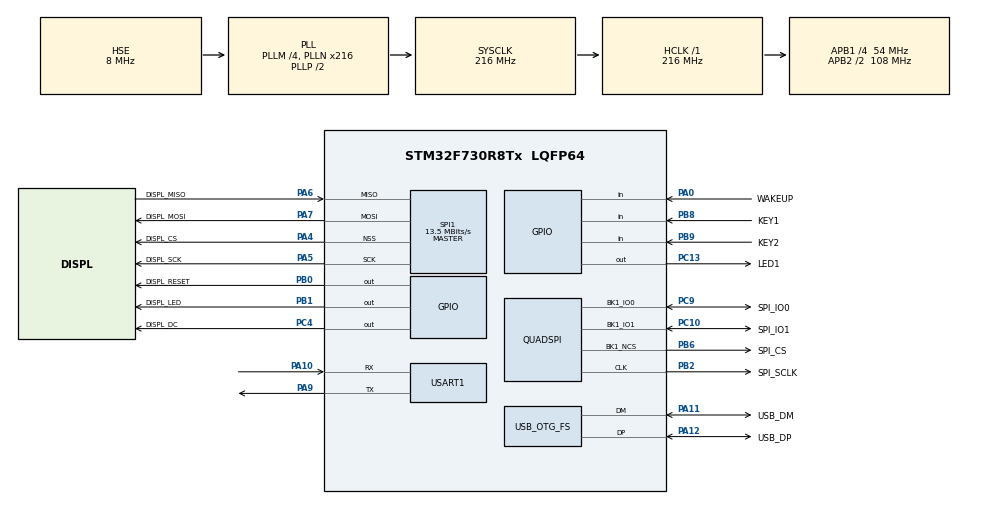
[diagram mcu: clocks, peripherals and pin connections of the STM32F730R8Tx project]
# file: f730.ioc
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CORTEX_M7.ART_ACCLERATOR_ENABLE=1
CORTEX_M7.AccessPermission-Cortex_Memory_Protection_Unit_Region0_Settings=MPU_REGION_FULL_ACCESS
CORTEX_M7.BaseAddress-Cortex_Memory_Protection_Unit_Region0_Settings=0x90000000
CORTEX_M7.CPU_DCache=Disabled
CORTEX_M7.CPU_ICache=Enabled
CORTEX_M7.DisableExec-Cortex_Memory_Protection_Unit_Region0_Settings=MPU_INSTRUCTION_ACCESS_ENABLE
CORTEX_M7.Enable-Cortex_Memory_Protection_Unit_Region0_Settings=MPU_REGION_ENABLE
CORTEX_M7.FlashInterface=TCM_Enabled
CORTEX_M7.IsCacheable-Cortex_Memory_Protection_Unit_Region0_Settings=MPU_ACCESS_CACHEABLE
CORTEX_M7.IsShareable-Cortex_Memory_Protection_Unit_Region0_Settings=MPU_ACCESS_NOT_SHAREABLE
CORTEX_M7.MPU_Control=MPU_PRIVILEGED_DEFAULT
CORTEX_M7.PREFETCH_ENABLE=1
CORTEX_M7.Size-Cortex_Memory_Protection_Unit_Region0_Settings=MPU_REGION_SIZE_4MB
FATFS._FS_EXFAT=1
FATFS._USE_LFN=2
FREERTOS.Tasks01=LogicTask,24,4028,BusinessLogicTask,Default,NULL,Dynamic,NULL,NULL
FREERTOS.configTOTAL_HEAP_SIZE=150360
Mcu.Family=STM32F7
Mcu.Name=STM32F730R8Tx
Mcu.Package=LQFP64
NVIC.OTG_FS_IRQn=true\:5\:0\:true\:false\:true\:false\:false\:true
NVIC.PriorityGroup=NVIC_PRIORITYGROUP_4
NVIC.USART1_IRQn=true\:5\:0\:true\:false\:true\:false\:true\:true
PA0-WKUP.GPIO_Label=WAKEUP
PA0-WKUP.Signal=GPIO_Input
PA10.Mode=Asynchronous
PA10.Signal=USART1_RX
PA11.GPIO_Label=USB_DM
PA11.Mode=Host_Only
PA11.Signal=USB_OTG_FS_DM
PA12.GPIO_Label=USB_DP
PA12.Mode=Host_Only
PA12.Signal=USB_OTG_FS_DP
PA13.GPIO_Label=SWDIO
PA13.Mode=Serial_Wire
PA13.Signal=SYS_JTMS-SWDIO
PA14.GPIO_Label=SWCLK
PA14.Mode=Serial_Wire
PA14.Signal=SYS_JTCK-SWCLK
PA4.GPIO_Label=DISPL_CS
PA4.Mode=NSS_Signal_Hard_Output
PA4.Signal=SPI1_NSS
PA5.GPIO_Label=DISPL_SCK
PA5.Mode=Full_Duplex_Master
PA5.Signal=SPI1_SCK
PA6.GPIO_Label=DISPL_MISO
PA6.Mode=Full_Duplex_Master
PA6.Signal=SPI1_MISO
PA7.GPIO_Label=DISPL_MOSI
PA7.Mode=Full_Duplex_Master
PA7.Signal=SPI1_MOSI
PA9.Mode=Asynchronous
PA9.Signal=USART1_TX
PB0.GPIO_Label=DISPL_RESET
PB0.Signal=GPIO_Output
PB1.GPIO_Label=DISPL_LED
PB1.Signal=GPIO_Output
PB2.GPIO_Label=SPI_SCLK
PB2.Mode=Single Bank 1 2IOs
PB2.Signal=QUADSPI_CLK
PB6.GPIO_Label=SPI_CS
PB6.Mode=Single Bank 1 2IOs
PB6.Signal=QUADSPI_BK1_NCS
PB8.GPIO_Label=KEY1
PB8.Signal=GPIO_Input
PB9.GPIO_Label=KEY2
PB9.Signal=GPIO_Input
PC10.GPIO_Label=SPI_IO1
PC10.Mode=Single Bank 1 2IOs
PC10.Signal=QUADSPI_BK1_IO1
PC13.GPIO_Label=LED1
PC13.Signal=GPIO_Output
PC14-OSC32_IN.Mode=LSE-External-Oscillator
PC14-OSC32_IN.Signal=RCC_OSC32_IN
PC15-OSC32_OUT.Mode=LSE-External-Oscillator
PC15-OSC32_OUT.Signal=RCC_OSC32_OUT
PC4.GPIO_Label=DISPL_DC
PC4.Signal=GPIO_Output
PC9.GPIO_Label=SPI_IO0
PC9.Mode=Single Bank 1 2IOs
PC9.Signal=QUADSPI_BK1_IO0
PH0-OSC_IN.Mode=HSE-External-Oscillator
PH0-OSC_IN.Signal=RCC_OSC_IN
PH1-OSC_OUT.Mode=HSE-External-Oscillator
PH1-OSC_OUT.Signal=RCC_OSC_OUT
ProjectManager.HeapSize=0x8200
ProjectManager.StackSize=0x200
ProjectManager.TargetToolchain=STM32CubeIDE
QUADSPI.ChipSelectHighTime=QSPI_CS_HIGH_TIME_1_CYCLE
QUADSPI.ClockPrescaler=10
QUADSPI.FifoThreshold=4
QUADSPI.FlashSize=21
QUADSPI.SampleShifting=QSPI_SAMPLE_SHIFTING_NONE
RCC.AHBFreq_Value=216000000
RCC.APB1CLKDivider=RCC_HCLK_DIV4
RCC.APB1Freq_Value=54000000
RCC.APB1TimFreq_Value=108000000
RCC.APB2CLKDivider=RCC_HCLK_DIV2
RCC.APB2Freq_Value=108000000
RCC.APB2TimFreq_Value=216000000
RCC.CortexFreq_Value=216000000
RCC.EnbaleCSS=true
RCC.HCLKFreq_Value=216000000
RCC.HSE_VALUE=8000000
RCC.HSI_VALUE=16000000
RCC.PLLM=4
RCC.PLLN=216
RCC.PLLQ=9
RCC.SYSCLKFreq_VALUE=216000000
RCC.SYSCLKSource=RCC_SYSCLKSOURCE_PLLCLK
RCC.USBFreq_Value=48000000
RCC.VCOOutputFreq_Value=432000000
SPI1.BaudRatePrescaler=SPI_BAUDRATEPRESCALER_8
SPI1.CalculateBaudRate=13.5 MBits/s
SPI1.DataSize=SPI_DATASIZE_8BIT
SPI1.Direction=SPI_DIRECTION_2LINES
SPI1.Mode=SPI_MODE_MASTER
SPI1.VirtualNSS=VM_NSSHARD
SPI1.VirtualType=VM_MASTER
USART1.VirtualMode-Asynchronous=VM_ASYNC
USB_HOST.USBH_HandleTypeDef-MSC_FS=hUsbHostFS
USB_HOST.USBH_USE_OS-MSC_FS=0
USB_HOST.VirtualModeFS=Msc
USB_OTG_FS.VirtualMode=Host_Only
USB_OTG_FS.phy_itface=HCD_PHY_EMBEDDED
VP_FATFS_VS_USB.Mode=USB
VP_FREERTOS_VS_CMSIS_V2.Mode=CMSIS_V2
VP_USB_HOST_VS_USB_HOST_MSC_FS.Mode=MSC_FS
board=custom

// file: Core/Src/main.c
/* USER CODE BEGIN Header */
/**
  ******************************************************************************
  * @file           : main.c
  * @brief          : Main program body
  ******************************************************************************
  * @attention
  *
  * <h2><center>&copy; Copyright (c) 2020 STMicroelectronics.
  * All rights reserved.</center></h2>
  *
  * This software component is licensed by ST under Ultimate Liberty license
  * SLA0044, the "License"; You may not use this file except in compliance with
  * the License. You may obtain a copy of the License at:
  *                             www.st.com/SLA0044
  *
  ******************************************************************************
  */
/* USER CODE END Header */
#include "main.h"
#include "cmsis_os.h"
#include "fatfs.h"
#include "usb_host.h"

/* USER CODE BEGIN Includes */
#include "dqspi.h"
#include "app_config.h"

/* USER CODE END Includes */

QSPI_HandleTypeDef hqspi;

SPI_HandleTypeDef hspi1;

UART_HandleTypeDef huart1;

/* Definitions for LogicTask */
osThreadId_t LogicTaskHandle;
const osThreadAttr_t LogicTask_attributes = {
  .name = "LogicTask",
  .priority = (osPriority_t) osPriorityNormal,
  .stack_size = 4028 * 4
};

void SystemClock_Config(void);
static void MPU_Config(void);
static void MX_GPIO_Init(void);
static void MX_QUADSPI_Init(void);
static void MX_USART1_UART_Init(void);
static void MX_SPI1_Init(void);
void BusinessLogicTask(void *argument);

int main(void)
{

  /* MPU Configuration--------------------------------------------------------*/
  MPU_Config();

  /* Enable I-Cache---------------------------------------------------------*/
  SCB_EnableICache();

  /* MCU Configuration--------------------------------------------------------*/

  /* Reset of all peripherals, Initializes the Flash interface and the Systick. */
  HAL_Init();

  /* Configure the system clock */
  SystemClock_Config();

  /* Initialize all configured peripherals */
  MX_GPIO_Init();
  MX_QUADSPI_Init();
  MX_USART1_UART_Init();
  MX_FATFS_Init();
  MX_SPI1_Init();
  /* USER CODE BEGIN 2 */
  DQSpiMemoryMapped();

  /* USER CODE END 2 */

  /* Init scheduler */
  osKernelInitialize();

  /* Create the thread(s) */
  /* creation of LogicTask */
  LogicTaskHandle = osThreadNew(BusinessLogicTask, NULL, &LogicTask_attributes);

  /* Start scheduler */
  osKernelStart();

  /* We should never get here as control is now taken by the scheduler */
  /* Infinite loop */
  while (1)
  {

  }
}

void SystemClock_Config(void)
{
  RCC_OscInitTypeDef RCC_OscInitStruct = {0};
  RCC_ClkInitTypeDef RCC_ClkInitStruct = {0};
  RCC_PeriphCLKInitTypeDef PeriphClkInitStruct = {0};

  /** Configure LSE Drive Capability
  */
  HAL_PWR_EnableBkUpAccess();
  /** Configure the main internal regulator output voltage
  */
  __HAL_RCC_PWR_CLK_ENABLE();
  __HAL_PWR_VOLTAGESCALING_CONFIG(PWR_REGULATOR_VOLTAGE_SCALE1);
  /** Initializes the RCC Oscillators according to the specified parameters
  * in the RCC_OscInitTypeDef structure.
  */
  RCC_OscInitStruct.OscillatorType = RCC_OSCILLATORTYPE_HSE;
  RCC_OscInitStruct.HSEState = RCC_HSE_ON;
  RCC_OscInitStruct.PLL.PLLState = RCC_PLL_ON;
  RCC_OscInitStruct.PLL.PLLSource = RCC_PLLSOURCE_HSE;
  RCC_OscInitStruct.PLL.PLLM = 4;
  RCC_OscInitStruct.PLL.PLLN = 216;
  RCC_OscInitStruct.PLL.PLLP = RCC_PLLP_DIV2;
  RCC_OscInitStruct.PLL.PLLQ = 9;
  if (HAL_RCC_OscConfig(&RCC_OscInitStruct) != HAL_OK)
  {
    Error_Handler();
  }
  /** Activate the Over-Drive mode
  */
  if (HAL_PWREx_EnableOverDrive() != HAL_OK)
  {
    Error_Handler();
  }
  /** Initializes the CPU, AHB and APB buses clocks
  */
  RCC_ClkInitStruct.ClockType = RCC_CLOCKTYPE_HCLK|RCC_CLOCKTYPE_SYSCLK
                              |RCC_CLOCKTYPE_PCLK1|RCC_CLOCKTYPE_PCLK2;
  RCC_ClkInitStruct.SYSCLKSource = RCC_SYSCLKSOURCE_PLLCLK;
  RCC_ClkInitStruct.AHBCLKDivider = RCC_SYSCLK_DIV1;
  RCC_ClkInitStruct.APB1CLKDivider = RCC_HCLK_DIV4;
  RCC_ClkInitStruct.APB2CLKDivider = RCC_HCLK_DIV2;

  if (HAL_RCC_ClockConfig(&RCC_ClkInitStruct, FLASH_LATENCY_7) != HAL_OK)
  {
    Error_Handler();
  }
  PeriphClkInitStruct.PeriphClockSelection = RCC_PERIPHCLK_USART1|RCC_PERIPHCLK_CLK48;
  PeriphClkInitStruct.Usart1ClockSelection = RCC_USART1CLKSOURCE_PCLK2;
  PeriphClkInitStruct.Clk48ClockSelection = RCC_CLK48SOURCE_PLL;
  if (HAL_RCCEx_PeriphCLKConfig(&PeriphClkInitStruct) != HAL_OK)
  {
    Error_Handler();
  }
  /** Enables the Clock Security System
  */
  HAL_RCC_EnableCSS();
}

static void MX_QUADSPI_Init(void)
{

  /* QUADSPI parameter configuration*/
  hqspi.Instance = QUADSPI;
  hqspi.Init.ClockPrescaler = 10;
  hqspi.Init.FifoThreshold = 4;
  hqspi.Init.SampleShifting = QSPI_SAMPLE_SHIFTING_NONE;
  hqspi.Init.FlashSize = 21;
  hqspi.Init.ChipSelectHighTime = QSPI_CS_HIGH_TIME_1_CYCLE;
  hqspi.Init.ClockMode = QSPI_CLOCK_MODE_0;
  hqspi.Init.FlashID = QSPI_FLASH_ID_1;
  hqspi.Init.DualFlash = QSPI_DUALFLASH_DISABLE;
  if (HAL_QSPI_Init(&hqspi) != HAL_OK)
  {
    Error_Handler();
  }

}

static void MX_SPI1_Init(void)
{

  /* SPI1 parameter configuration*/
  hspi1.Instance = SPI1;
  hspi1.Init.Mode = SPI_MODE_MASTER;
  hspi1.Init.Direction = SPI_DIRECTION_2LINES;
  hspi1.Init.DataSize = SPI_DATASIZE_8BIT;
  hspi1.Init.CLKPolarity = SPI_POLARITY_LOW;
  hspi1.Init.CLKPhase = SPI_PHASE_1EDGE;
  hspi1.Init.NSS = SPI_NSS_HARD_OUTPUT;
  hspi1.Init.BaudRatePrescaler = SPI_BAUDRATEPRESCALER_8;
  hspi1.Init.FirstBit = SPI_FIRSTBIT_MSB;
  hspi1.Init.TIMode = SPI_TIMODE_DISABLE;
  hspi1.Init.CRCCalculation = SPI_CRCCALCULATION_DISABLE;
  hspi1.Init.CRCPolynomial = 7;
  hspi1.Init.CRCLength = SPI_CRC_LENGTH_DATASIZE;
  hspi1.Init.NSSPMode = SPI_NSS_PULSE_ENABLE;
  if (HAL_SPI_Init(&hspi1) != HAL_OK)
  {
    Error_Handler();
  }

}

static void MX_USART1_UART_Init(void)
{

  huart1.Instance = USART1;
  huart1.Init.BaudRate = 115200;
  huart1.Init.WordLength = UART_WORDLENGTH_8B;
  huart1.Init.StopBits = UART_STOPBITS_1;
  huart1.Init.Parity = UART_PARITY_NONE;
  huart1.Init.Mode = UART_MODE_TX_RX;
  huart1.Init.HwFlowCtl = UART_HWCONTROL_NONE;
  huart1.Init.OverSampling = UART_OVERSAMPLING_16;
  huart1.Init.OneBitSampling = UART_ONE_BIT_SAMPLE_DISABLE;
  huart1.AdvancedInit.AdvFeatureInit = UART_ADVFEATURE_NO_INIT;
  if (HAL_UART_Init(&huart1) != HAL_OK)
  {
    Error_Handler();
  }

}

static void MX_GPIO_Init(void)
{
  GPIO_InitTypeDef GPIO_InitStruct = {0};

  /* GPIO Ports Clock Enable */
  __HAL_RCC_GPIOC_CLK_ENABLE();
  __HAL_RCC_GPIOH_CLK_ENABLE();
  __HAL_RCC_GPIOA_CLK_ENABLE();
  __HAL_RCC_GPIOB_CLK_ENABLE();

  /*Configure GPIO pin Output Level */
  HAL_GPIO_WritePin(GPIOC, LED1_Pin|DISPL_DC_Pin, GPIO_PIN_RESET);

  /*Configure GPIO pin Output Level */
  HAL_GPIO_WritePin(GPIOB, DISPL_RESET_Pin|DISPL_LED_Pin, GPIO_PIN_RESET);

  /*Configure GPIO pins : LED1_Pin DISPL_DC_Pin */
  GPIO_InitStruct.Pin = LED1_Pin|DISPL_DC_Pin;
  GPIO_InitStruct.Mode = GPIO_MODE_OUTPUT_PP;
  GPIO_InitStruct.Pull = GPIO_NOPULL;
  GPIO_InitStruct.Speed = GPIO_SPEED_FREQ_LOW;
  HAL_GPIO_Init(GPIOC, &GPIO_InitStruct);

  /*Configure GPIO pin : WAKEUP_Pin */
  GPIO_InitStruct.Pin = WAKEUP_Pin;
  GPIO_InitStruct.Mode = GPIO_MODE_INPUT;
  GPIO_InitStruct.Pull = GPIO_NOPULL;
  HAL_GPIO_Init(WAKEUP_GPIO_Port, &GPIO_InitStruct);

  /*Configure GPIO pins : DISPL_RESET_Pin DISPL_LED_Pin */
  GPIO_InitStruct.Pin = DISPL_RESET_Pin|DISPL_LED_Pin;
  GPIO_InitStruct.Mode = GPIO_MODE_OUTPUT_PP;
  GPIO_InitStruct.Pull = GPIO_NOPULL;
  GPIO_InitStruct.Speed = GPIO_SPEED_FREQ_LOW;
  HAL_GPIO_Init(GPIOB, &GPIO_InitStruct);

  /*Configure GPIO pins : KEY1_Pin KEY2_Pin */
  GPIO_InitStruct.Pin = KEY1_Pin|KEY2_Pin;
  GPIO_InitStruct.Mode = GPIO_MODE_INPUT;
  GPIO_InitStruct.Pull = GPIO_NOPULL;
  HAL_GPIO_Init(GPIOB, &GPIO_InitStruct);

}

void BusinessLogicTask(void *argument)
{
  /* init code for USB_HOST */
  MX_USB_HOST_Init();
  /* USER CODE BEGIN 5 */
#if APP_TEST_FLASH_EN
  AppTestFlash();
#elif APP_LED_TOGGLE_EN
  BusinessLogic();
#elif APP_LVGL_BUTTON_EN
  HmiLvglExample();
#endif

  for (;;) {
	  osDelay(100);
  }
  /* USER CODE END 5 */
}

/* MPU Configuration */

void MPU_Config(void)
{
  MPU_Region_InitTypeDef MPU_InitStruct = {0};

  /* Disables the MPU */
  HAL_MPU_Disable();
  /** Initializes and configures the Region and the memory to be protected
  */
  MPU_InitStruct.Enable = MPU_REGION_ENABLE;
  MPU_InitStruct.Number = MPU_REGION_NUMBER0;
  MPU_InitStruct.BaseAddress = 0x90000000;
  MPU_InitStruct.Size = MPU_REGION_SIZE_4MB;
  MPU_InitStruct.SubRegionDisable = 0x0;
  MPU_InitStruct.TypeExtField = MPU_TEX_LEVEL0;
  MPU_InitStruct.AccessPermission = MPU_REGION_FULL_ACCESS;
  MPU_InitStruct.DisableExec = MPU_INSTRUCTION_ACCESS_ENABLE;
  MPU_InitStruct.IsShareable = MPU_ACCESS_NOT_SHAREABLE;
  MPU_InitStruct.IsCacheable = MPU_ACCESS_CACHEABLE;
  MPU_InitStruct.IsBufferable = MPU_ACCESS_NOT_BUFFERABLE;

  HAL_MPU_ConfigRegion(&MPU_InitStruct);
  /* Enables the MPU */
  HAL_MPU_Enable(MPU_PRIVILEGED_DEFAULT);

}

void Error_Handler(void)
{
}

/************************ (C) COPYRIGHT STMicroelectronics *****END OF FILE****/
